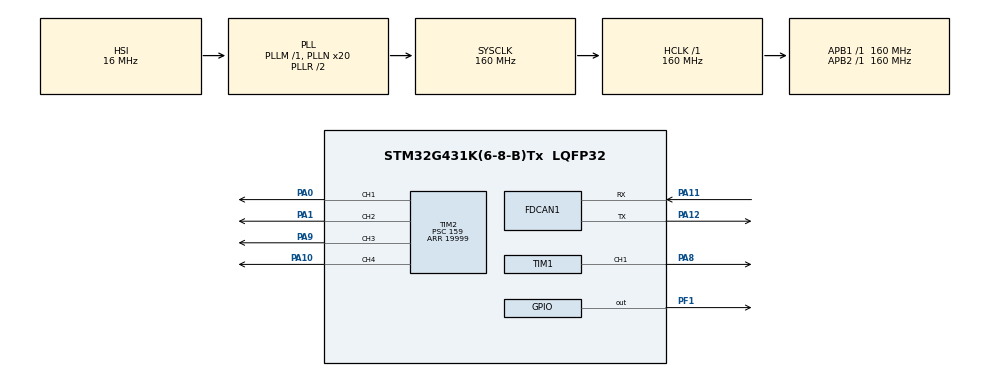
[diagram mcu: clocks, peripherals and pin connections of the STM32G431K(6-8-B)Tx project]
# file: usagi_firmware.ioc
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FDCAN1.CalculateBaudRateNominal=1000000
FDCAN1.CalculateTimeBitNominal=1000
FDCAN1.CalculateTimeQuantumNominal=6.25
FDCAN1.DataSyncJumpWidth=6
FDCAN1.DataTimeSeg1=25
FDCAN1.DataTimeSeg2=6
FDCAN1.ExtFiltersNbr=1
FDCAN1.FrameFormat=FDCAN_FRAME_FD_BRS
FDCAN1.NominalPrescaler=1
FDCAN1.NominalSyncJumpWidth=32
FDCAN1.NominalTimeSeg1=127
FDCAN1.NominalTimeSeg2=32
Mcu.Family=STM32G4
Mcu.Name=STM32G431K(6-8-B)Tx
Mcu.Package=LQFP32
NUCLEO-G431KB.LD2=true
NUCLEO-G431KB.VCP=true
NVIC.FDCAN1_IT0_IRQn=true\:5\:0\:true\:false\:true\:true\:true\:true
NVIC.FDCAN1_IT1_IRQn=true\:5\:0\:true\:false\:true\:true\:true\:true
NVIC.PriorityGroup=NVIC_PRIORITYGROUP_4
NVIC.TIM1_TRG_COM_TIM17_IRQn=true\:5\:0\:true\:false\:true\:true\:true\:true
NVIC.TIM6_DAC_IRQn=true\:0\:0\:true\:false\:true\:false\:true\:true
NVIC.TimeBase=TIM6_DAC_IRQn
NVIC.TimeBaseIP=TIM6
PA0.Signal=S_TIM2_CH1
PA1.Signal=S_TIM2_CH2
PA10.Signal=S_TIM2_CH4
PA11.Mode=FDCAN_Activate
PA11.Signal=FDCAN1_RX
PA12.Mode=FDCAN_Activate
PA12.Signal=FDCAN1_TX
PA13.GPIO_Label=T_SWDIO
PA13.Mode=Trace_Asynchronous_SW
PA13.Signal=SYS_JTMS-SWDIO
PA14.GPIO_Label=T_SWCLK
PA14.Mode=Trace_Asynchronous_SW
PA14.Signal=SYS_JTCK-SWCLK
PA2.Signal=USART2_TX
PA3.Signal=USART2_RX
PA8.Signal=S_TIM1_CH1
PA9.Signal=S_TIM2_CH3
PB3.GPIO_Label=T_SWO
PB3.Mode=Trace_Asynchronous_SW
PB3.Signal=SYS_JTDO-SWO
PF1-OSC_OUT.Signal=GPIO_Output
ProjectManager.HeapSize=0x200
ProjectManager.StackSize=0x400
ProjectManager.TargetToolchain=CMake
RCC.ADC12Freq_Value=160000000
RCC.AHBFreq_Value=160000000
RCC.APB1Freq_Value=160000000
RCC.APB1TimFreq_Value=160000000
RCC.APB2Freq_Value=160000000
RCC.APB2TimFreq_Value=160000000
RCC.CortexFreq_Value=160000000
RCC.EXTERNAL_CLOCK_VALUE=12288000
RCC.HCLKFreq_Value=160000000
RCC.HSE_VALUE=8000000
RCC.HSI48_VALUE=48000000
RCC.HSI_VALUE=16000000
RCC.LSE_VALUE=32768
RCC.PLLN=20
RCC.SYSCLKFreq_VALUE=160000000
RCC.SYSCLKSource=RCC_SYSCLKSOURCE_PLLCLK
RCC.USBFreq_Value=160000000
RCC.VCOOutputFreq_Value=320000000
SH.S_TIM1_CH1.0=TIM1_CH1,PWM Generation1 CH1
SH.S_TIM2_CH1.0=TIM2_CH1,PWM Generation1 CH1
SH.S_TIM2_CH2.0=TIM2_CH2,PWM Generation2 CH2
SH.S_TIM2_CH3.0=TIM2_CH3,PWM Generation3 CH3
SH.S_TIM2_CH4.0=TIM2_CH4,PWM Generation4 CH4
TIM1.Channel-PWM\ Generation1\ CH1=TIM_CHANNEL_1
TIM1.PeriodNoDither=999
TIM1.Prescaler=7
TIM17.PeriodNoDither=999
TIM17.Prescaler=159
TIM2.Channel-PWM\ Generation1\ CH1=TIM_CHANNEL_1
TIM2.Channel-PWM\ Generation2\ CH2=TIM_CHANNEL_2
TIM2.Channel-PWM\ Generation3\ CH3=TIM_CHANNEL_3
TIM2.Channel-PWM\ Generation4\ CH4=TIM_CHANNEL_4
TIM2.PeriodNoDither=19999
TIM2.Prescaler=159
TIM2.PulseNoDither_1=1500
TIM2.PulseNoDither_2=1500
TIM2.PulseNoDither_3=1500
TIM2.PulseNoDither_4=1500
VP_NUCLEO-G431KB_VS_BSP_COMMON.Mode=COMMON
VP_SYS_VS_DBSignals.Mode=DisableDeadBatterySignals
VP_SYS_VS_tim6.Mode=TIM6
VP_TIM17_VS_ClockSourceINT.Mode=Enable_Timer
board=NUCLEO-G431KB

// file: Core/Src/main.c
/* USER CODE BEGIN Header */
/**
  ******************************************************************************
  * @file           : main.c
  * @brief          : Main program body
  ******************************************************************************
  * @attention
  *
  * Copyright (c) 2026 STMicroelectronics.
  * All rights reserved.
  *
  * This software is licensed under terms that can be found in the LICENSE file
  * in the root directory of this software component.
  * If no LICENSE file comes with this software, it is provided AS-IS.
  *
  ******************************************************************************
  */
/* USER CODE END Header */
#include "main.h"
#include "fdcan.h"
#include "tim.h"
#include "gpio.h"

/* USER CODE BEGIN Includes */
#include <string.h>

#include "FreeRTOS.h"
#include "task.h"

#include "led_blink_node.h"
#include "cyphal_node.h"
#include "actuator_command.h"

/* USER CODE END Includes */

COM_InitTypeDef BspCOMInit;

void SystemClock_Config(void);

int main(void)
{

  /* MCU Configuration--------------------------------------------------------*/

  /* Reset of all peripherals, Initializes the Flash interface and the Systick. */
  HAL_Init();

  /* Configure the system clock */
  SystemClock_Config();

  /* Initialize all configured peripherals */
  MX_GPIO_Init();
  MX_FDCAN1_Init();
  MX_TIM1_Init();
  MX_TIM2_Init();
  MX_TIM17_Init();
  /* USER CODE BEGIN 2 */
  if (!cyphal_node_init()) {
    Error_Handler();
  }
  actuator_command_init();
  /* USER CODE END 2 */

  /* Initialize leds */
  BSP_LED_Init(LED_GREEN);

  /* Initialize COM1 port (115200, 8 bits (7-bit data + 1 stop bit), no parity */
  BspCOMInit.BaudRate   = 115200;
  BspCOMInit.WordLength = COM_WORDLENGTH_8B;
  BspCOMInit.StopBits   = COM_STOPBITS_1;
  BspCOMInit.Parity     = COM_PARITY_NONE;
  BspCOMInit.HwFlowCtl  = COM_HWCONTROL_NONE;
  if (BSP_COM_Init(COM1, &BspCOMInit) != BSP_ERROR_NONE)
  {
    Error_Handler();
  }

  /* Infinite loop */
  /* USER CODE BEGIN WHILE */
  xTaskCreate(LEDBlinkTask, "LedBlink", configMINIMAL_STACK_SIZE*1, NULL, 1, NULL);
  xTaskCreate(CyphalControlTask, "CyphalCtrl", configMINIMAL_STACK_SIZE*4, NULL, 2, NULL);
  vTaskStartScheduler();

  while (1)
  {

    /* USER CODE END WHILE */

  }
}

void SystemClock_Config(void)
{
  RCC_OscInitTypeDef RCC_OscInitStruct = {0};
  RCC_ClkInitTypeDef RCC_ClkInitStruct = {0};

  /** Configure the main internal regulator output voltage
  */
  HAL_PWREx_ControlVoltageScaling(PWR_REGULATOR_VOLTAGE_SCALE1_BOOST);

  /** Initializes the RCC Oscillators according to the specified parameters
  * in the RCC_OscInitTypeDef structure.
  */
  RCC_OscInitStruct.OscillatorType = RCC_OSCILLATORTYPE_HSI;
  RCC_OscInitStruct.HSIState = RCC_HSI_ON;
  RCC_OscInitStruct.HSICalibrationValue = RCC_HSICALIBRATION_DEFAULT;
  RCC_OscInitStruct.PLL.PLLState = RCC_PLL_ON;
  RCC_OscInitStruct.PLL.PLLSource = RCC_PLLSOURCE_HSI;
  RCC_OscInitStruct.PLL.PLLM = RCC_PLLM_DIV1;
  RCC_OscInitStruct.PLL.PLLN = 20;
  RCC_OscInitStruct.PLL.PLLP = RCC_PLLP_DIV2;
  RCC_OscInitStruct.PLL.PLLQ = RCC_PLLQ_DIV2;
  RCC_OscInitStruct.PLL.PLLR = RCC_PLLR_DIV2;
  if (HAL_RCC_OscConfig(&RCC_OscInitStruct) != HAL_OK)
  {
    Error_Handler();
  }

  /** Initializes the CPU, AHB and APB buses clocks
  */
  RCC_ClkInitStruct.ClockType = RCC_CLOCKTYPE_HCLK|RCC_CLOCKTYPE_SYSCLK
                              |RCC_CLOCKTYPE_PCLK1|RCC_CLOCKTYPE_PCLK2;
  RCC_ClkInitStruct.SYSCLKSource = RCC_SYSCLKSOURCE_PLLCLK;
  RCC_ClkInitStruct.AHBCLKDivider = RCC_SYSCLK_DIV1;
  RCC_ClkInitStruct.APB1CLKDivider = RCC_HCLK_DIV1;
  RCC_ClkInitStruct.APB2CLKDivider = RCC_HCLK_DIV1;

  if (HAL_RCC_ClockConfig(&RCC_ClkInitStruct, FLASH_LATENCY_4) != HAL_OK)
  {
    Error_Handler();
  }
}

/* USER CODE BEGIN 4 */

void vApplicationStackOverflowHook( TaskHandle_t xTask, char *pcTaskName )
{
  char* uart_mes = " Stack Over Flow!\r\n";
  HAL_UART_Transmit(&hcom_uart[COM1], (uint8_t*)uart_mes, strlen(uart_mes), 1000);
}

/* USER CODE END 4 */

void HAL_TIM_PeriodElapsedCallback(TIM_HandleTypeDef *htim)
{
  if (htim->Instance == TIM6)
  {
    HAL_IncTick();
  }
}
/* USER CODE BEGIN Header */
/**
  ******************************************************************************
  * @file           : main.c
  * @brief          : Main program body
  ******************************************************************************
  * @attention
  *
  * Copyright (c) 2026 STMicroelectronics.
  * All rights reserved.
  *
  * This software is licensed under terms that can be found in the LICENSE file
  * in the root directory of this software component.
  * If no LICENSE file comes with this software, it is provided AS-IS.
  *
  ******************************************************************************
  */
/* USER CODE END Header */

void Error_Handler(void)
{
  __disable_irq();
  while (1)
  {
  }
}
